# STM32F40x register map
File version: 1.5
Registers are 32-bit, read-write, reset 0x0 unless marked. A register's access mark holds for its fields unless they carry their own. Offsets are from the block's base; [hi:lo] are bit positions; {n}, {i} and the like mark numbered series.

## CAN1（控制器局域网） — 控制器局域网：差分串行通信 | Controller area network
Base 0x40006400
Same registers: CAN2（控制器局域网） 0x40006800
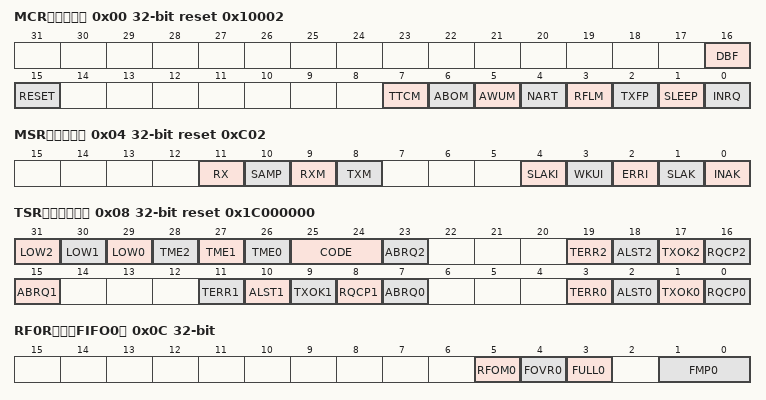
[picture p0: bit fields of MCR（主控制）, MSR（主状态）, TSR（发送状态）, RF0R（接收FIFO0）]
0x00 MCR（主控制） reset 0x10002 — 初始化/睡眠/时间戳 | master control register
  [16] DBF, [15] RESET, [7] TTCM, [6] ABOM, [5] AWUM, [4] NART, [3] RFLM, [2] TXFP, [1] SLEEP, [0] INRQ
0x04 MSR（主状态） access per field reset 0xC02 — 初始化确认/错误状态 | master status register
  [11] RX ro, [10] SAMP ro, [9] RXM ro, [8] TXM ro, [4] SLAKI rw, [3] WKUI rw, [2] ERRI rw, [1] SLAK ro, [0] INAK ro
0x08 TSR（发送状态） access per field reset 0x1C000000 — 发送邮箱状态 | transmit status register
  [31] LOW2 ro — Lowest priority flag for mailbox 2
  [30] LOW1 ro — Lowest priority flag for mailbox 1
  [29] LOW0 ro — Lowest priority flag for mailbox 0
  [28] TME2 ro — Lowest priority flag for mailbox 2
  [27] TME1 ro — Lowest priority flag for mailbox 1
  [26] TME0 ro — Lowest priority flag for mailbox 0
  [25:24] CODE ro
  [23] ABRQ2 rw
  [19] TERR2 rw
  [18] ALST2 rw
  [17] TXOK2 rw
  [16] RQCP2 rw
  [15] ABRQ1 rw
  [11] TERR1 rw
  [10] ALST1 rw
  [9] TXOK1 rw
  [8] RQCP1 rw
  [7] ABRQ0 rw
  [3] TERR0 rw
  [2] ALST0 rw
  [1] TXOK0 rw
  [0] RQCP0 rw
0x0C RF0R（接收FIFO0） access per field — 接收 FIFO 0 状态 | receive FIFO 0 register
  [5] RFOM0 rw, [4] FOVR0 rw, [3] FULL0 rw, [1:0] FMP0 ro
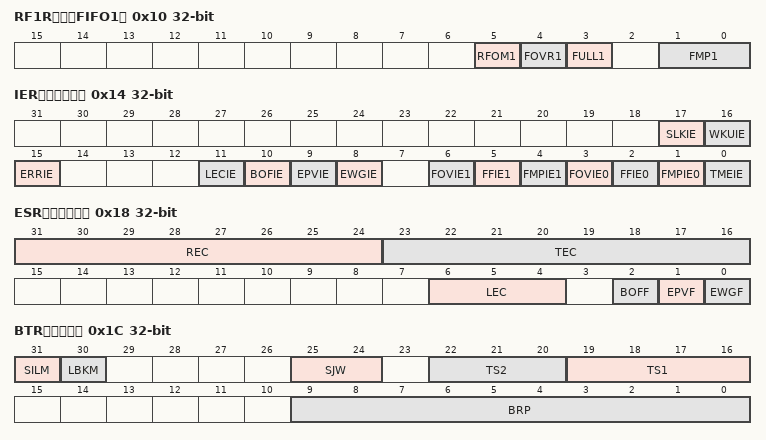
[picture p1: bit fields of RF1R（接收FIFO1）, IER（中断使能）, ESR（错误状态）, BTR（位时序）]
0x10 RF1R（接收FIFO1） access per field — 接收 FIFO 1 状态 | receive FIFO 1 register
  [5] RFOM1 rw, [4] FOVR1 rw, [3] FULL1 rw, [1:0] FMP1 ro
0x14 IER（中断使能） — 中断使能 | interrupt enable register
  [17] SLKIE, [16] WKUIE, [15] ERRIE, [11] LECIE, [10] BOFIE, [9] EPVIE, [8] EWGIE, [6] FOVIE1, [5] FFIE1, [4] FMPIE1, [3] FOVIE0, [2] FFIE0, [1] FMPIE0, [0] TMEIE
0x18 ESR（错误状态） access per field — 错误标志/计数 | interrupt enable register
  [31:24] REC ro, [23:16] TEC ro, [6:4] LEC rw, [2] BOFF ro, [1] EPVF ro, [0] EWGF ro
0x1C BTR（位时序） — 波特率/同步跳转/采样点 | bit timing register
  [31] SILM, [30] LBKM, [25:24] SJW, [22:20] TS2, [19:16] TS1, [9:0] BRP
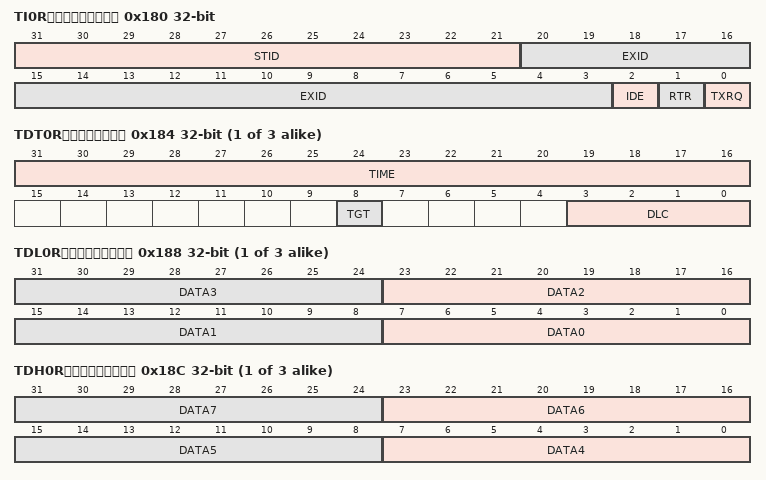
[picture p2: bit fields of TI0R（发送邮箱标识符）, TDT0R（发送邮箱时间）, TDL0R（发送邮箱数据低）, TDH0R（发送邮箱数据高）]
0x180 TI0R（发送邮箱标识符） — 发送邮箱 0 标识符 | TX mailbox identifier register
  [31:21] STID, [20:3] EXID, [2] IDE, [1] RTR, [0] TXRQ
{0x184+0x10*i} TDT{i}R（发送邮箱时间） (i=0..2) — 发送邮箱 {i} 数据时间 | mailbox data length control and time stamp register
  [31:16] TIME, [8] TGT, [3:0] DLC
{0x188+0x10*i} TDL{i}R（发送邮箱数据低） (i=0..2) — 发送邮箱 {i} 数据低 | mailbox data low register
  [8n+7:8n] DATA{n} (n=0..3)
{0x18C+0x10*i} TDH{i}R（发送邮箱数据高） (i=0..2) — 发送邮箱 {i} 数据高 | mailbox data high register
  [8n-25:8n-32] DATA{n} (n=4..7)
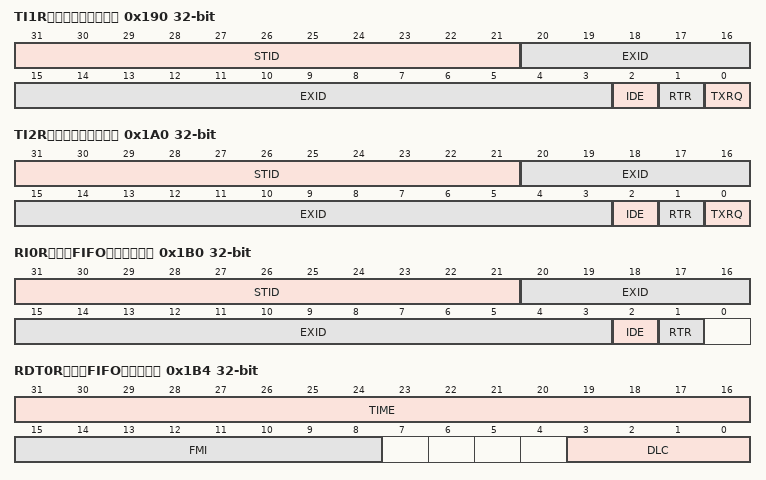
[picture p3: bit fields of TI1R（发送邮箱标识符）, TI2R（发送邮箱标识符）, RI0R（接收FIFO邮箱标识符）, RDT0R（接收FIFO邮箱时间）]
0x190 TI1R（发送邮箱标识符） — 发送邮箱 1 标识符 | mailbox identifier register
  [31:21] STID, [20:3] EXID, [2] IDE, [1] RTR, [0] TXRQ
0x1A0 TI2R（发送邮箱标识符） — 发送邮箱 2 标识符 | mailbox identifier register
  [31:21] STID, [20:3] EXID, [2] IDE, [1] RTR, [0] TXRQ
0x1B0 RI0R（接收FIFO邮箱标识符） ro — 接收 FIFO 邮箱 0 标识符 | receive FIFO mailbox identifier register
  [31:21] STID, [20:3] EXID, [2] IDE, [1] RTR
0x1B4 RDT0R（接收FIFO邮箱时间） ro — 接收 FIFO 邮箱 0 数据时间 | mailbox data high register
  [31:16] TIME, [15:8] FMI, [3:0] DLC
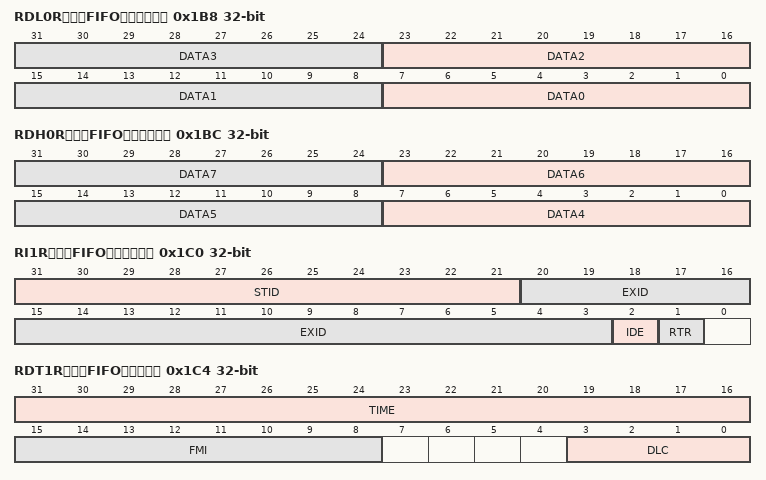
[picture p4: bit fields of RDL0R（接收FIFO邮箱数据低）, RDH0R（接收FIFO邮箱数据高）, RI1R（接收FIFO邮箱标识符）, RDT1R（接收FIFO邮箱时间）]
0x1B8 RDL0R（接收FIFO邮箱数据低） ro — 接收 FIFO 邮箱 0 数据低 | mailbox data high register
  [8n+7:8n] DATA{n} (n=0..3)
0x1BC RDH0R（接收FIFO邮箱数据高） ro — 接收 FIFO 邮箱 0 数据高 | receive FIFO mailbox data high register
  [8n-25:8n-32] DATA{n} (n=4..7)
0x1C0 RI1R（接收FIFO邮箱标识符） ro — 接收 FIFO 邮箱 1 标识符 | mailbox data high register
  [31:21] STID, [20:3] EXID, [2] IDE, [1] RTR
0x1C4 RDT1R（接收FIFO邮箱时间） ro — 接收 FIFO 邮箱 1 数据时间 | mailbox data high register
  [31:16] TIME, [15:8] FMI, [3:0] DLC
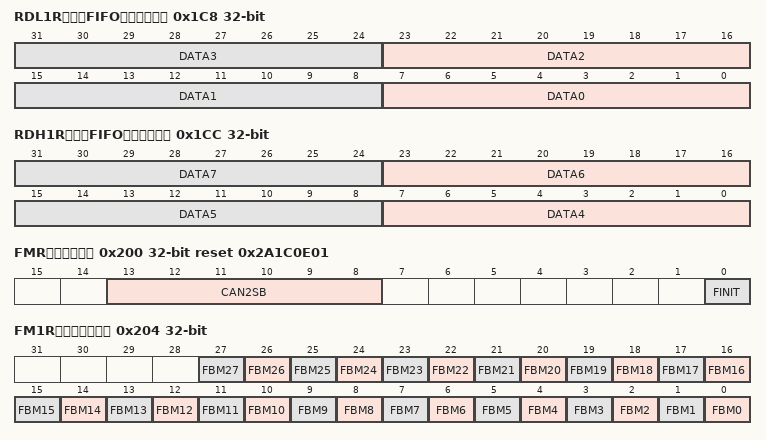
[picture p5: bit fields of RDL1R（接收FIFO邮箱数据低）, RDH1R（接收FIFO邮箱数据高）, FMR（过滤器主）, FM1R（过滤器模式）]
0x1C8 RDL1R（接收FIFO邮箱数据低） ro — 接收 FIFO 邮箱 1 数据低 | mailbox data high register
  [8n+7:8n] DATA{n} (n=0..3)
0x1CC RDH1R（接收FIFO邮箱数据高） ro — 接收 FIFO 邮箱 1 数据高 | mailbox data high register
  [8n-25:8n-32] DATA{n} (n=4..7)
0x200 FMR（过滤器主） reset 0x2A1C0E01 — 过滤器主控制（激活/模式） | filter master register
  [13:8] CAN2SB, [0] FINIT
0x204 FM1R（过滤器模式） — 过滤器位宽模式 | filter mode register
  [n] FBM{n} (n=0..27) — Filter mode
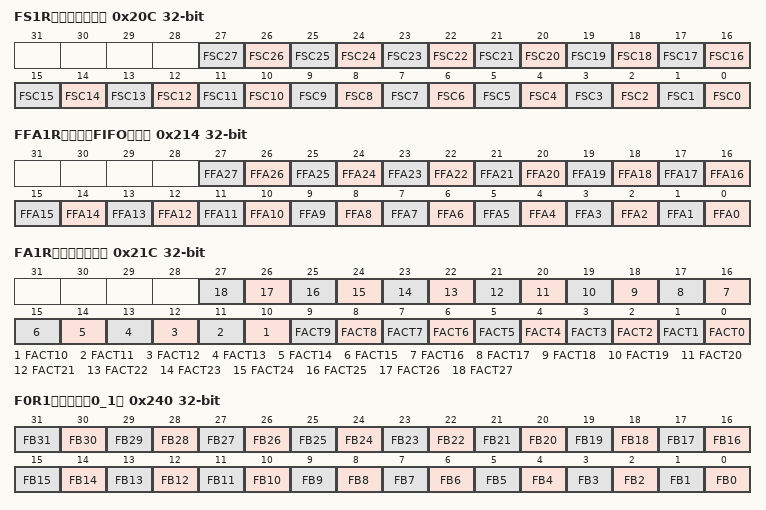
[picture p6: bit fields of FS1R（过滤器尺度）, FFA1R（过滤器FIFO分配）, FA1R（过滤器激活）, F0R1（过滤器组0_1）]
0x20C FS1R（过滤器尺度） — 过滤器单/双 32 位尺度 | filter scale register
  [n] FSC{n} (n=0..27) — Filter scale configuration
0x214 FFA1R（过滤器FIFO分配） — 过滤器分配至 FIFO0/1 | filter FIFO assignment register
  [n] FFA{n} (n=0..27) — Filter FIFO assignment for filter {n}
0x21C FA1R（过滤器激活） — 过滤器激活 | filter activation register
  [n] FACT{n} (n=0..27) — Filter active
0x240 F0R1（过滤器组0_1） — 过滤器组 0 寄存器 1 | Filter bank 0 register 1
  [n] FB{n} (n=0..31) — Filter bits
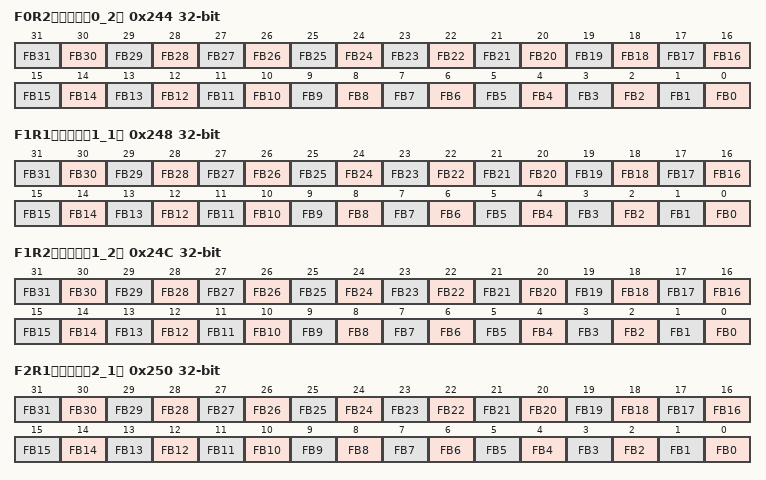
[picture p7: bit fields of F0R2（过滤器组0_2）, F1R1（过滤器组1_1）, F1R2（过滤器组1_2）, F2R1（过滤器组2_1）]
0x244 F0R2（过滤器组0_2） — 过滤器组 0 寄存器 2 | Filter bank 0 register 2
  [n] FB{n} (n=0..31) — Filter bits
0x248 F1R1（过滤器组1_1） — 过滤器组 1 寄存器 1 | Filter bank 1 register 1
  [n] FB{n} (n=0..31) — Filter bits
0x24C F1R2（过滤器组1_2） — 过滤器组 1 寄存器 2 | Filter bank 1 register 2
  [n] FB{n} (n=0..31) — Filter bits
0x250 F2R1（过滤器组2_1） — 过滤器组 2 寄存器 1 | Filter bank 2 register 1
  [n] FB{n} (n=0..31) — Filter bits
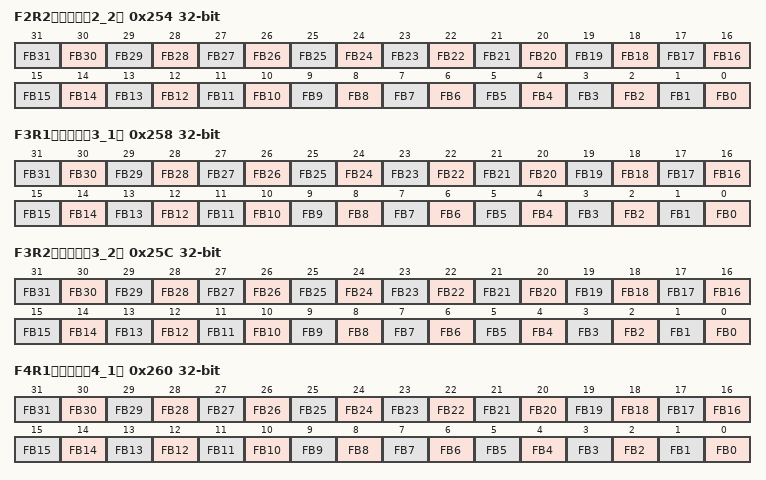
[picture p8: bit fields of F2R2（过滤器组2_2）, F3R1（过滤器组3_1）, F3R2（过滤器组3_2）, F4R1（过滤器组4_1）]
0x254 F2R2（过滤器组2_2） — 过滤器组 2 寄存器 2 | Filter bank 2 register 2
  [n] FB{n} (n=0..31) — Filter bits
0x258 F3R1（过滤器组3_1） — 过滤器组 3 寄存器 1 | Filter bank 3 register 1
  [n] FB{n} (n=0..31) — Filter bits
0x25C F3R2（过滤器组3_2） — 过滤器组 3 寄存器 2 | Filter bank 3 register 2
  [n] FB{n} (n=0..31) — Filter bits
0x260 F4R1（过滤器组4_1） — 过滤器组 4 寄存器 1 | Filter bank 4 register 1
  [n] FB{n} (n=0..31) — Filter bits
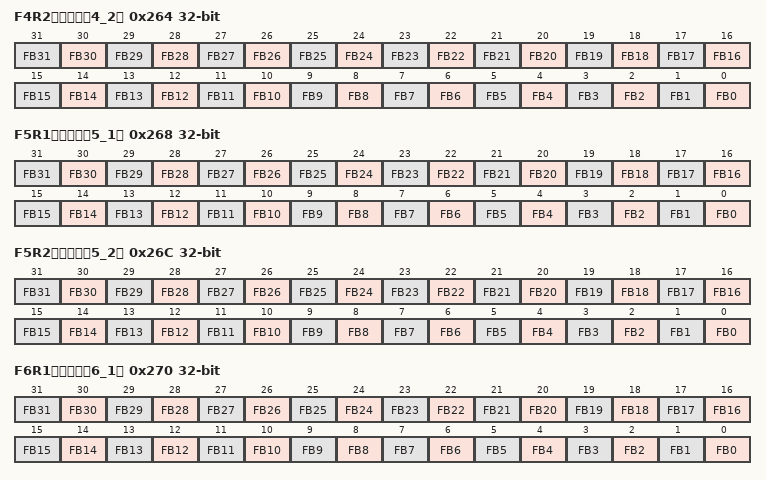
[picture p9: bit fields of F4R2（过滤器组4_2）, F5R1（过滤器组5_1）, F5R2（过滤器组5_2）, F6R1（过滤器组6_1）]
0x264 F4R2（过滤器组4_2） — 过滤器组 4 寄存器 2 | Filter bank 4 register 2
  [n] FB{n} (n=0..31) — Filter bits
0x268 F5R1（过滤器组5_1） — 过滤器组 5 寄存器 1 | Filter bank 5 register 1
  [n] FB{n} (n=0..31) — Filter bits
0x26C F5R2（过滤器组5_2） — 过滤器组 5 寄存器 2 | Filter bank 5 register 2
  [n] FB{n} (n=0..31) — Filter bits
0x270 F6R1（过滤器组6_1） — 过滤器组 6 寄存器 1 | Filter bank 6 register 1
  [n] FB{n} (n=0..31) — Filter bits
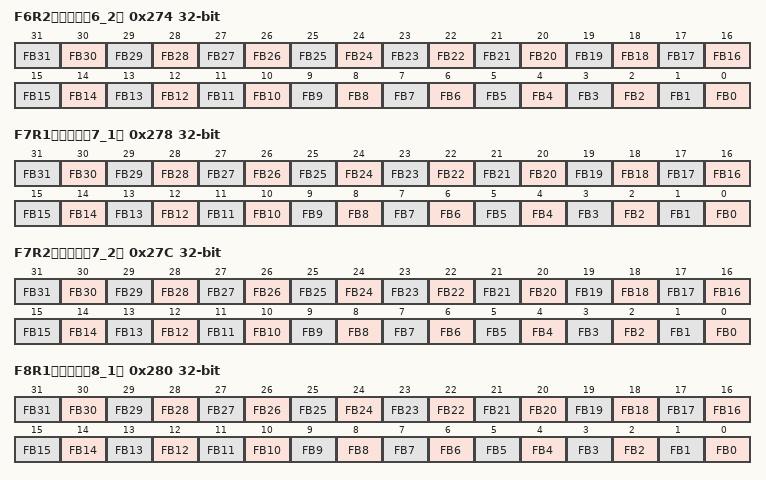
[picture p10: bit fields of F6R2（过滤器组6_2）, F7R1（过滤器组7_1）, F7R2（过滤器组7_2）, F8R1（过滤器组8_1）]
0x274 F6R2（过滤器组6_2） — 过滤器组 6 寄存器 2 | Filter bank 6 register 2
  [n] FB{n} (n=0..31) — Filter bits
0x278 F7R1（过滤器组7_1） — 过滤器组 7 寄存器 1 | Filter bank 7 register 1
  [n] FB{n} (n=0..31) — Filter bits
0x27C F7R2（过滤器组7_2） — 过滤器组 7 寄存器 2 | Filter bank 7 register 2
  [n] FB{n} (n=0..31) — Filter bits
0x280 F8R1（过滤器组8_1） — 过滤器组 8 寄存器 1 | Filter bank 8 register 1
  [n] FB{n} (n=0..31) — Filter bits
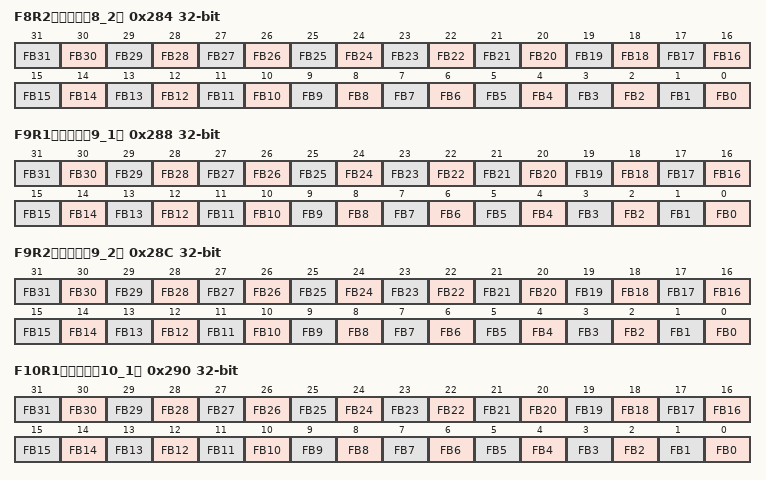
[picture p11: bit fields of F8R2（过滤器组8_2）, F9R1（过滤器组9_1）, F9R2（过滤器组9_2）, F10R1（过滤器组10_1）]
0x284 F8R2（过滤器组8_2） — 过滤器组 8 寄存器 2 | Filter bank 8 register 2
  [n] FB{n} (n=0..31) — Filter bits
0x288 F9R1（过滤器组9_1） — 过滤器组 9 寄存器 1 | Filter bank 9 register 1
  [n] FB{n} (n=0..31) — Filter bits
0x28C F9R2（过滤器组9_2） — 过滤器组 9 寄存器 2 | Filter bank 9 register 2
  [n] FB{n} (n=0..31) — Filter bits
0x290 F10R1（过滤器组10_1） — 过滤器组 10 寄存器 1 | Filter bank 10 register 1
  [n] FB{n} (n=0..31) — Filter bits
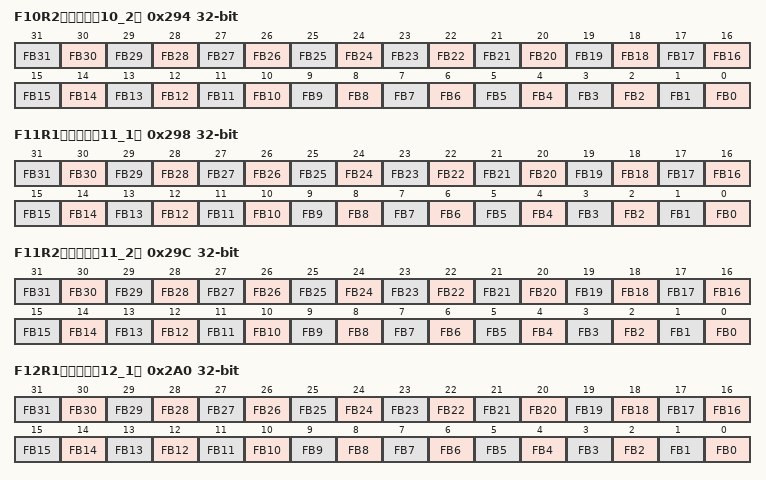
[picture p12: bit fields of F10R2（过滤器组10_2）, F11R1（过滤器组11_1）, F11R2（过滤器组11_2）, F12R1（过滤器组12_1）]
0x294 F10R2（过滤器组10_2） — 过滤器组 10 寄存器 2 | Filter bank 10 register 2
  [n] FB{n} (n=0..31) — Filter bits
0x298 F11R1（过滤器组11_1） — 过滤器组 11 寄存器 1 | Filter bank 11 register 1
  [n] FB{n} (n=0..31) — Filter bits
0x29C F11R2（过滤器组11_2） — 过滤器组 11 寄存器 2 | Filter bank 11 register 2
  [n] FB{n} (n=0..31) — Filter bits
0x2A0 F12R1（过滤器组12_1） — 过滤器组 12 寄存器 1 | Filter bank 4 register 1
  [n] FB{n} (n=0..31) — Filter bits
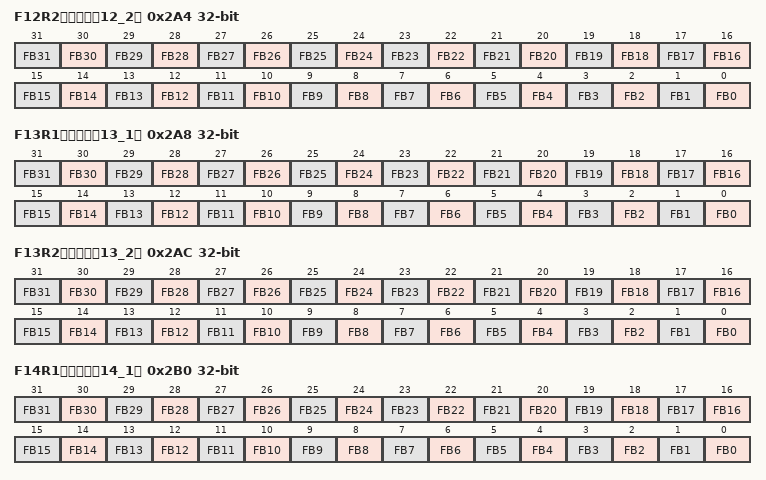
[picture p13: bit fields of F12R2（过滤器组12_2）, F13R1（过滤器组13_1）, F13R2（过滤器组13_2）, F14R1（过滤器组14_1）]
0x2A4 F12R2（过滤器组12_2） — 过滤器组 12 寄存器 2 | Filter bank 12 register 2
  [n] FB{n} (n=0..31) — Filter bits
0x2A8 F13R1（过滤器组13_1） — 过滤器组 13 寄存器 1 | Filter bank 13 register 1
  [n] FB{n} (n=0..31) — Filter bits
0x2AC F13R2（过滤器组13_2） — 过滤器组 13 寄存器 2 | Filter bank 13 register 2
  [n] FB{n} (n=0..31) — Filter bits
0x2B0 F14R1（过滤器组14_1） — 过滤器组 14 寄存器 1 | Filter bank 14 register 1
  [n] FB{n} (n=0..31) — Filter bits
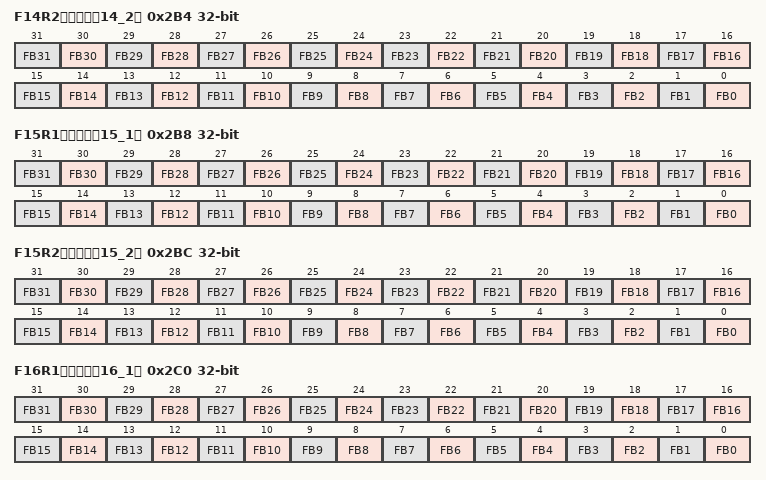
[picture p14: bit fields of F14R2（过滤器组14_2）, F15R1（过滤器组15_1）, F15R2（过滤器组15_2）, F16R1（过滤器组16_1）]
0x2B4 F14R2（过滤器组14_2） — 过滤器组 14 寄存器 2 | Filter bank 14 register 2
  [n] FB{n} (n=0..31) — Filter bits
0x2B8 F15R1（过滤器组15_1） — 过滤器组 15 寄存器 1 | Filter bank 15 register 1
  [n] FB{n} (n=0..31) — Filter bits
0x2BC F15R2（过滤器组15_2） — 过滤器组 15 寄存器 2 | Filter bank 15 register 2
  [n] FB{n} (n=0..31) — Filter bits
0x2C0 F16R1（过滤器组16_1） — 过滤器组 16 寄存器 1 | Filter bank 16 register 1
  [n] FB{n} (n=0..31) — Filter bits
0x2C4 F16R2（过滤器组16_2） — 过滤器组 16 寄存器 2 | Filter bank 16 register 2
  [n] FB{n} (n=0..31) — Filter bits
0x2C8 F17R1（过滤器组17_1） — 过滤器组 17 寄存器 1 | Filter bank 17 register 1
  [n] FB{n} (n=0..31) — Filter bits
0x2CC F17R2（过滤器组17_2） — 过滤器组 17 寄存器 2 | Filter bank 17 register 2
  [n] FB{n} (n=0..31) — Filter bits
0x2D0 F18R1（过滤器组18_1） — 过滤器组 18 寄存器 1 | Filter bank 18 register 1
  [n] FB{n} (n=0..31) — Filter bits
0x2D4 F18R2（过滤器组18_2） — 过滤器组 18 寄存器 2 | Filter bank 18 register 2
  [n] FB{n} (n=0..31) — Filter bits
0x2D8 F19R1（过滤器组19_1） — 过滤器组 19 寄存器 1 | Filter bank 19 register 1
  [n] FB{n} (n=0..31) — Filter bits
0x2DC F19R2（过滤器组19_2） — 过滤器组 19 寄存器 2 | Filter bank 19 register 2
  [n] FB{n} (n=0..31) — Filter bits
0x2E0 F20R1（过滤器组20_1） — 过滤器组 20 寄存器 1 | Filter bank 20 register 1
  [n] FB{n} (n=0..31) — Filter bits
0x2E4 F20R2（过滤器组20_2） — 过滤器组 20 寄存器 2 | Filter bank 20 register 2
  [n] FB{n} (n=0..31) — Filter bits
0x2E8 F21R1（过滤器组21_1） — 过滤器组 21 寄存器 1 | Filter bank 21 register 1
  [n] FB{n} (n=0..31) — Filter bits
0x2EC F21R2（过滤器组21_2） — 过滤器组 21 寄存器 2 | Filter bank 21 register 2
  [n] FB{n} (n=0..31) — Filter bits
0x2F0 F22R1（过滤器组22_1） — 过滤器组 22 寄存器 1 | Filter bank 22 register 1
  [n] FB{n} (n=0..31) — Filter bits
0x2F4 F22R2（过滤器组22_2） — 过滤器组 22 寄存器 2 | Filter bank 22 register 2
  [n] FB{n} (n=0..31) — Filter bits
0x2F8 F23R1（过滤器组23_1） — 过滤器组 23 寄存器 1 | Filter bank 23 register 1
  [n] FB{n} (n=0..31) — Filter bits
0x2FC F23R2（过滤器组23_2） — 过滤器组 23 寄存器 2 | Filter bank 23 register 2
  [n] FB{n} (n=0..31) — Filter bits
0x300 F24R1（过滤器组24_1） — 过滤器组 24 寄存器 1 | Filter bank 24 register 1
  [n] FB{n} (n=0..31) — Filter bits
0x304 F24R2（过滤器组24_2） — 过滤器组 24 寄存器 2 | Filter bank 24 register 2
  [n] FB{n} (n=0..31) — Filter bits
0x308 F25R1（过滤器组25_1） — 过滤器组 25 寄存器 1 | Filter bank 25 register 1
  [n] FB{n} (n=0..31) — Filter bits
0x30C F25R2（过滤器组25_2） — 过滤器组 25 寄存器 2 | Filter bank 25 register 2
  [n] FB{n} (n=0..31) — Filter bits
0x310 F26R1（过滤器组26_1） — 过滤器组 26 寄存器 1 | Filter bank 26 register 1
  [n] FB{n} (n=0..31) — Filter bits
0x314 F26R2（过滤器组26_2） — 过滤器组 26 寄存器 2 | Filter bank 26 register 2
  [n] FB{n} (n=0..31) — Filter bits
0x318 F27R1（过滤器组27_1） — 过滤器组 27 寄存器 1 | Filter bank 27 register 1
  [n] FB{n} (n=0..31) — Filter bits
0x31C F27R2（过滤器组27_2） — 过滤器组 27 寄存器 2 | Filter bank 27 register 2
  [n] FB{n} (n=0..31) — Filter bits
